AUTOSAR XML (schema 4-0-3)
package /ComponentTypes
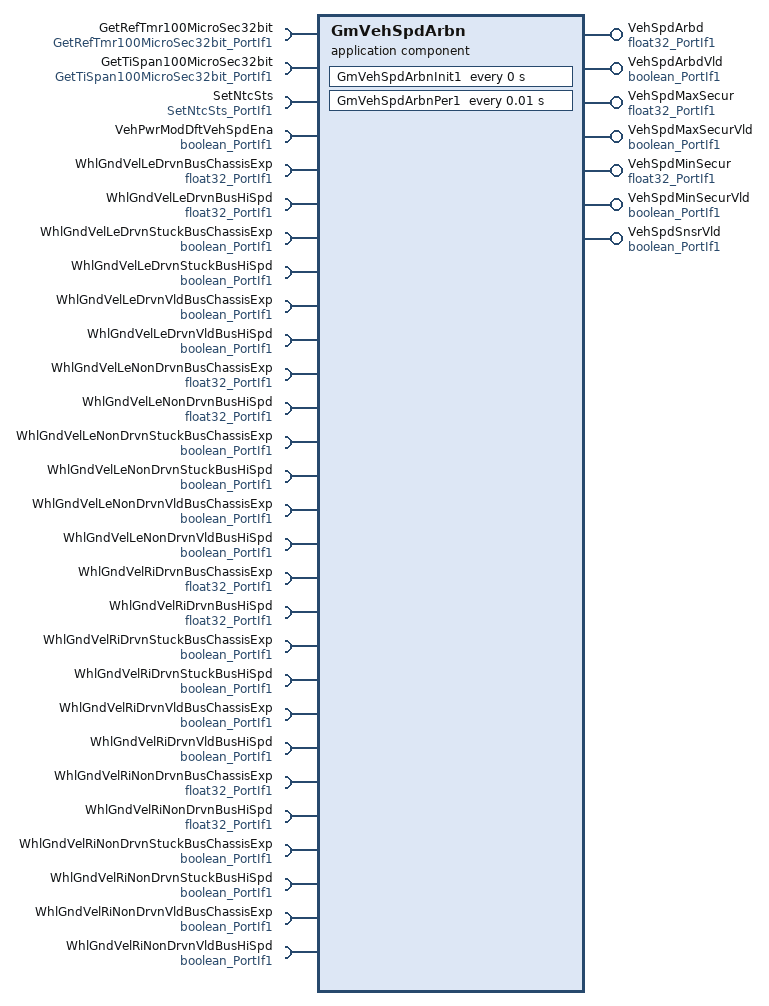
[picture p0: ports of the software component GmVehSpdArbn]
  application sw component type GmVehSpdArbn
    7 x provide port:
      VehSpdArbd: nonqueued-sender-com-spec{data-element=Val, init-value=0}, provided-interface=float32_PortIf1
      VehSpdArbdVld: nonqueued-sender-com-spec{data-element=Logl, init-value=0}, provided-interface=boolean_PortIf1
      VehSpdMaxSecur: nonqueued-sender-com-spec{data-element=Val, init-value=0}, provided-interface=float32_PortIf1
      VehSpdMaxSecurVld: nonqueued-sender-com-spec{data-element=Logl, init-value=0}, provided-interface=boolean_PortIf1
      VehSpdMinSecur: nonqueued-sender-com-spec{data-element=Val, init-value=0}, provided-interface=float32_PortIf1
      VehSpdMinSecurVld: nonqueued-sender-com-spec{data-element=Logl, init-value=0}, provided-interface=boolean_PortIf1
      VehSpdSnsrVld: nonqueued-sender-com-spec{data-element=Logl, init-value=0}, provided-interface=boolean_PortIf1
    28 x require port:
      GetRefTmr100MicroSec32bit: required-interface=GetRefTmr100MicroSec32bit_PortIf1
      GetTiSpan100MicroSec32bit: required-interface=GetTiSpan100MicroSec32bit_PortIf1
      SetNtcSts: required-interface=SetNtcSts_PortIf1
      VehPwrModDftVehSpdEna: nonqueued-receiver-com-spec{data-element=Logl, filter=data-filter-type=ALWAYS, init-value=0}, required-interface=boolean_PortIf1
      WhlGndVelLeDrvnBusChassisExp: nonqueued-receiver-com-spec{data-element=Val, filter=data-filter-type=ALWAYS, init-value=0}, required-interface=float32_PortIf1
      WhlGndVelLeDrvnBusHiSpd: nonqueued-receiver-com-spec{data-element=Val, filter=data-filter-type=ALWAYS, init-value=0}, required-interface=float32_PortIf1
      WhlGndVelLeDrvnStuckBusChassisExp: nonqueued-receiver-com-spec{data-element=Logl, filter=data-filter-type=ALWAYS, init-value=0}, required-interface=boolean_PortIf1
      WhlGndVelLeDrvnStuckBusHiSpd: nonqueued-receiver-com-spec{data-element=Logl, filter=data-filter-type=ALWAYS, init-value=0}, required-interface=boolean_PortIf1
      WhlGndVelLeDrvnVldBusChassisExp: nonqueued-receiver-com-spec{data-element=Logl, filter=data-filter-type=ALWAYS, init-value=0}, required-interface=boolean_PortIf1
      WhlGndVelLeDrvnVldBusHiSpd: nonqueued-receiver-com-spec{data-element=Logl, filter=data-filter-type=ALWAYS, init-value=0}, required-interface=boolean_PortIf1
      WhlGndVelLeNonDrvnBusChassisExp: nonqueued-receiver-com-spec{data-element=Val, filter=data-filter-type=ALWAYS, init-value=0}, required-interface=float32_PortIf1
      WhlGndVelLeNonDrvnBusHiSpd: nonqueued-receiver-com-spec{data-element=Val, filter=data-filter-type=ALWAYS, init-value=0}, required-interface=float32_PortIf1
      WhlGndVelLeNonDrvnStuckBusChassisExp: nonqueued-receiver-com-spec{data-element=Logl, filter=data-filter-type=ALWAYS, init-value=0}, required-interface=boolean_PortIf1
      WhlGndVelLeNonDrvnStuckBusHiSpd: nonqueued-receiver-com-spec{data-element=Logl, filter=data-filter-type=ALWAYS, init-value=0}, required-interface=boolean_PortIf1
      WhlGndVelLeNonDrvnVldBusChassisExp: nonqueued-receiver-com-spec{data-element=Logl, filter=data-filter-type=ALWAYS, init-value=0}, required-interface=boolean_PortIf1
      WhlGndVelLeNonDrvnVldBusHiSpd: nonqueued-receiver-com-spec{data-element=Logl, filter=data-filter-type=ALWAYS, init-value=0}, required-interface=boolean_PortIf1
      WhlGndVelRiDrvnBusChassisExp: nonqueued-receiver-com-spec{data-element=Val, filter=data-filter-type=ALWAYS, init-value=0}, required-interface=float32_PortIf1
      WhlGndVelRiDrvnBusHiSpd: nonqueued-receiver-com-spec{data-element=Val, filter=data-filter-type=ALWAYS, init-value=0}, required-interface=float32_PortIf1
      WhlGndVelRiDrvnStuckBusChassisExp: nonqueued-receiver-com-spec{data-element=Logl, filter=data-filter-type=ALWAYS, init-value=0}, required-interface=boolean_PortIf1
      WhlGndVelRiDrvnStuckBusHiSpd: nonqueued-receiver-com-spec{data-element=Logl, filter=data-filter-type=ALWAYS, init-value=0}, required-interface=boolean_PortIf1
      WhlGndVelRiDrvnVldBusChassisExp: nonqueued-receiver-com-spec{data-element=Logl, filter=data-filter-type=ALWAYS, init-value=0}, required-interface=boolean_PortIf1
      WhlGndVelRiDrvnVldBusHiSpd: nonqueued-receiver-com-spec{data-element=Logl, filter=data-filter-type=ALWAYS, init-value=0}, required-interface=boolean_PortIf1
      WhlGndVelRiNonDrvnBusChassisExp: nonqueued-receiver-com-spec{data-element=Val, filter=data-filter-type=ALWAYS, init-value=0}, required-interface=float32_PortIf1
      WhlGndVelRiNonDrvnBusHiSpd: nonqueued-receiver-com-spec{data-element=Val, filter=data-filter-type=ALWAYS, init-value=0}, required-interface=float32_PortIf1
      WhlGndVelRiNonDrvnStuckBusChassisExp: nonqueued-receiver-com-spec{data-element=Logl, filter=data-filter-type=ALWAYS, init-value=0}, required-interface=boolean_PortIf1
      WhlGndVelRiNonDrvnStuckBusHiSpd: nonqueued-receiver-com-spec{data-element=Logl, filter=data-filter-type=ALWAYS, init-value=0}, required-interface=boolean_PortIf1
      WhlGndVelRiNonDrvnVldBusChassisExp: nonqueued-receiver-com-spec{data-element=Logl, filter=data-filter-type=ALWAYS, init-value=0}, required-interface=boolean_PortIf1
      WhlGndVelRiNonDrvnVldBusHiSpd: nonqueued-receiver-com-spec{data-element=Logl, filter=data-filter-type=ALWAYS, init-value=0}, required-interface=boolean_PortIf1
    behavior GmVehSpdArbn_InternalBehavior
      ar-typed-per-instance-memorys:
        5 x data, all with sw-calibration-access=READ-ONLY:
          dGmVehSpdArbnLeDrvnVld: type=boolean
          dGmVehSpdArbnLeNonDrvnVld: type=boolean
          dGmVehSpdArbnRiDrvnVld: type=boolean
          dGmVehSpdArbnRiNonDrvnVld: type=boolean
          DiagcRefTi: type=uint32
      timing event GmVehSpdArbn_InitEvent: start-on-event=GmVehSpdArbnInit1, period=0
      timing event TMT_GmVehSpdArbnPer1: start-on-event=GmVehSpdArbnPer1, period=0.01
      runnable GmVehSpdArbnInit1
        sync call SC_GetRefTmr100MicroSec32bit_Oper: operation=GetRefTmr100MicroSec32bit.Oper, timeout=0
      runnable GmVehSpdArbnPer1
        data-receive-point-by-arguments:
          25 x access:
            REC_VehPwrModDftVehSpdEna_Logl: accessed-variable=VehPwrModDftVehSpdEna.Logl
            REC_WhlGndVelLeDrvnBusChassisExp_Val: accessed-variable=WhlGndVelLeDrvnBusChassisExp.Val
            REC_WhlGndVelLeDrvnBusHiSpd_Val: accessed-variable=WhlGndVelLeDrvnBusHiSpd.Val
            REC_WhlGndVelLeDrvnStuckBusChassisExp_Logl: accessed-variable=WhlGndVelLeDrvnStuckBusChassisExp.Logl
            REC_WhlGndVelLeDrvnStuckBusHiSpd_Logl: accessed-variable=WhlGndVelLeDrvnStuckBusHiSpd.Logl
            REC_WhlGndVelLeDrvnVldBusChassisExp_Logl: accessed-variable=WhlGndVelLeDrvnVldBusChassisExp.Logl
            REC_WhlGndVelLeDrvnVldBusHiSpd_Logl: accessed-variable=WhlGndVelLeDrvnVldBusHiSpd.Logl
            REC_WhlGndVelLeNonDrvnBusChassisExp_Val: accessed-variable=WhlGndVelLeNonDrvnBusChassisExp.Val
            REC_WhlGndVelLeNonDrvnBusHiSpd_Val: accessed-variable=WhlGndVelLeNonDrvnBusHiSpd.Val
            REC_WhlGndVelLeNonDrvnStuckBusChassisExp_Logl: accessed-variable=WhlGndVelLeNonDrvnStuckBusChassisExp.Logl
            REC_WhlGndVelLeNonDrvnStuckBusHiSpd_Logl: accessed-variable=WhlGndVelLeNonDrvnStuckBusHiSpd.Logl
            REC_WhlGndVelLeNonDrvnVldBusChassisExp_Logl: accessed-variable=WhlGndVelLeNonDrvnVldBusChassisExp.Logl
            REC_WhlGndVelLeNonDrvnVldBusHiSpd_Logl: accessed-variable=WhlGndVelLeNonDrvnVldBusHiSpd.Logl
            REC_WhlGndVelRiDrvnBusChassisExp_Val: accessed-variable=WhlGndVelRiDrvnBusChassisExp.Val
            REC_WhlGndVelRiDrvnBusHiSpd_Val: accessed-variable=WhlGndVelRiDrvnBusHiSpd.Val
            REC_WhlGndVelRiDrvnStuckBusChassisExp_Logl: accessed-variable=WhlGndVelRiDrvnStuckBusChassisExp.Logl
            REC_WhlGndVelRiDrvnStuckBusHiSpd_Logl: accessed-variable=WhlGndVelRiDrvnStuckBusHiSpd.Logl
            REC_WhlGndVelRiDrvnVldBusChassisExp_Logl: accessed-variable=WhlGndVelRiDrvnVldBusChassisExp.Logl
            REC_WhlGndVelRiDrvnVldBusHiSpd_Logl: accessed-variable=WhlGndVelRiDrvnVldBusHiSpd.Logl
            REC_WhlGndVelRiNonDrvnBusChassisExp_Val: accessed-variable=WhlGndVelRiNonDrvnBusChassisExp.Val
            REC_WhlGndVelRiNonDrvnBusHiSpd_Val: accessed-variable=WhlGndVelRiNonDrvnBusHiSpd.Val
            REC_WhlGndVelRiNonDrvnStuckBusChassisExp_Logl: accessed-variable=WhlGndVelRiNonDrvnStuckBusChassisExp.Logl
            REC_WhlGndVelRiNonDrvnStuckBusHiSpd_Logl: accessed-variable=WhlGndVelRiNonDrvnStuckBusHiSpd.Logl
            REC_WhlGndVelRiNonDrvnVldBusChassisExp_Logl: accessed-variable=WhlGndVelRiNonDrvnVldBusChassisExp.Logl
            REC_WhlGndVelRiNonDrvnVldBusHiSpd_Logl: accessed-variable=WhlGndVelRiNonDrvnVldBusHiSpd.Logl
        data-send-points:
          7 x access:
            SEND_VehSpdArbd_Val: accessed-variable=VehSpdArbd.Val
            SEND_VehSpdArbdVld_Logl: accessed-variable=VehSpdArbdVld.Logl
            SEND_VehSpdMaxSecur_Val: accessed-variable=VehSpdMaxSecur.Val
            SEND_VehSpdMaxSecurVld_Logl: accessed-variable=VehSpdMaxSecurVld.Logl
            SEND_VehSpdMinSecur_Val: accessed-variable=VehSpdMinSecur.Val
            SEND_VehSpdMinSecurVld_Logl: accessed-variable=VehSpdMinSecurVld.Logl
            SEND_VehSpdSnsrVld_Logl: accessed-variable=VehSpdSnsrVld.Logl
        sync call SC_GetTiSpan100MicroSec32bit_Oper: operation=GetTiSpan100MicroSec32bit.Oper, timeout=0
        sync call SC_SetNtcSts_Oper: operation=SetNtcSts.Oper, timeout=0
  swc implementation GmVehSpdArbn_Implementation: behavior=GmVehSpdArbn_InternalBehavior
    code-descriptors:
      code Default: artifact-descriptors=autosar-engineering-object={short-label=Default, category=SWSRC}
